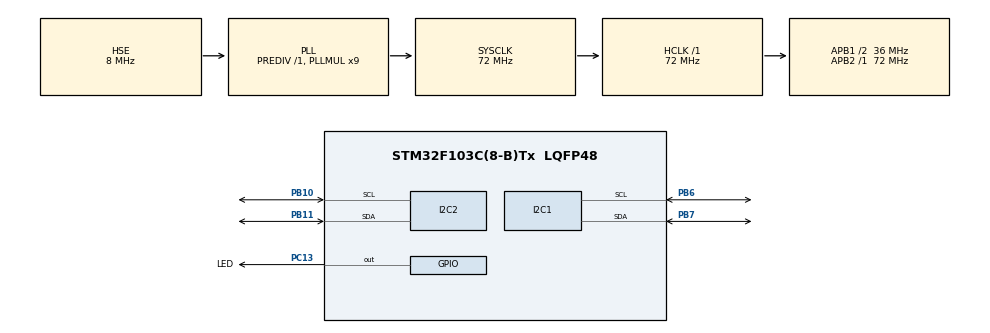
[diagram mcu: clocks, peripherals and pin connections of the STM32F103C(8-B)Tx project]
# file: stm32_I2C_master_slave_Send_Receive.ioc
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Dma.I2C1_RX.0.Direction=DMA_PERIPH_TO_MEMORY
Dma.I2C1_RX.0.Instance=DMA1_Channel7
Dma.I2C1_RX.0.MemDataAlignment=DMA_MDATAALIGN_BYTE
Dma.I2C1_RX.0.MemInc=DMA_MINC_ENABLE
Dma.I2C1_RX.0.Mode=DMA_NORMAL
Dma.I2C1_RX.0.PeriphDataAlignment=DMA_PDATAALIGN_BYTE
Dma.I2C1_RX.0.PeriphInc=DMA_PINC_DISABLE
Dma.I2C1_RX.0.Priority=DMA_PRIORITY_LOW
Dma.I2C1_TX.1.Direction=DMA_MEMORY_TO_PERIPH
Dma.I2C1_TX.1.Instance=DMA1_Channel6
Dma.I2C1_TX.1.MemDataAlignment=DMA_MDATAALIGN_BYTE
Dma.I2C1_TX.1.MemInc=DMA_MINC_ENABLE
Dma.I2C1_TX.1.Mode=DMA_NORMAL
Dma.I2C1_TX.1.PeriphDataAlignment=DMA_PDATAALIGN_BYTE
Dma.I2C1_TX.1.PeriphInc=DMA_PINC_DISABLE
Dma.I2C1_TX.1.Priority=DMA_PRIORITY_LOW
Dma.I2C2_RX.2.Direction=DMA_PERIPH_TO_MEMORY
Dma.I2C2_RX.2.Instance=DMA1_Channel5
Dma.I2C2_RX.2.MemDataAlignment=DMA_MDATAALIGN_BYTE
Dma.I2C2_RX.2.MemInc=DMA_MINC_ENABLE
Dma.I2C2_RX.2.Mode=DMA_NORMAL
Dma.I2C2_RX.2.PeriphDataAlignment=DMA_PDATAALIGN_BYTE
Dma.I2C2_RX.2.PeriphInc=DMA_PINC_DISABLE
Dma.I2C2_RX.2.Priority=DMA_PRIORITY_LOW
Dma.I2C2_TX.3.Direction=DMA_MEMORY_TO_PERIPH
Dma.I2C2_TX.3.Instance=DMA1_Channel4
Dma.I2C2_TX.3.MemDataAlignment=DMA_MDATAALIGN_BYTE
Dma.I2C2_TX.3.MemInc=DMA_MINC_ENABLE
Dma.I2C2_TX.3.Mode=DMA_NORMAL
Dma.I2C2_TX.3.PeriphDataAlignment=DMA_PDATAALIGN_BYTE
Dma.I2C2_TX.3.PeriphInc=DMA_PINC_DISABLE
Dma.I2C2_TX.3.Priority=DMA_PRIORITY_LOW
Dma.Request0=I2C1_RX
Dma.Request1=I2C1_TX
Dma.Request2=I2C2_RX
Dma.Request3=I2C2_TX
I2C1.I2C_Mode=I2C_Fast
I2C1.OwnAddress=I2C1_Address
I2C2.AddressingMode=I2C_ADDRESSINGMODE_7BIT
I2C2.I2C_Mode=I2C_Fast
I2C2.OwnAddress=I2C2_Address
Mcu.Family=STM32F1
Mcu.Name=STM32F103C(8-B)Tx
Mcu.Package=LQFP48
Mcu.UserConstants=I2C1_Address,0x15;I2C2_Address,0x16
NVIC.DMA1_Channel4_IRQn=true\:6\:0\:true\:false\:true\:false\:true
NVIC.DMA1_Channel5_IRQn=true\:6\:0\:true\:false\:true\:false\:true
NVIC.DMA1_Channel6_IRQn=true\:6\:0\:true\:false\:true\:false\:true
NVIC.DMA1_Channel7_IRQn=true\:6\:0\:true\:false\:true\:false\:true
NVIC.I2C1_EV_IRQn=true\:5\:0\:true\:false\:true\:true\:true
NVIC.I2C2_EV_IRQn=true\:5\:0\:true\:false\:true\:true\:true
NVIC.PriorityGroup=NVIC_PRIORITYGROUP_4
NVIC.TIM1_UP_IRQn=true\:0\:0\:false\:false\:true\:true\:true
PA13.Mode=Serial_Wire
PA13.Signal=SYS_JTMS-SWDIO
PA14.Mode=Serial_Wire
PA14.Signal=SYS_JTCK-SWCLK
PB10.Mode=I2C
PB10.Signal=I2C2_SCL
PB11.Mode=I2C
PB11.Signal=I2C2_SDA
PB6.Mode=I2C
PB6.Signal=I2C1_SCL
PB7.Mode=I2C
PB7.Signal=I2C1_SDA
PC13-TAMPER-RTC.GPIO_Label=LED
PC13-TAMPER-RTC.Signal=GPIO_Output
PD0-OSC_IN.Mode=HSE-External-Oscillator
PD0-OSC_IN.Signal=RCC_OSC_IN
PD1-OSC_OUT.Mode=HSE-External-Oscillator
PD1-OSC_OUT.Signal=RCC_OSC_OUT
ProjectManager.HeapSize=0x200
ProjectManager.StackSize=0x400
ProjectManager.TargetToolchain=STM32CubeIDE
RCC.AHBFreq_Value=72000000
RCC.APB1CLKDivider=RCC_HCLK_DIV2
RCC.APB1Freq_Value=36000000
RCC.APB1TimFreq_Value=72000000
RCC.APB2Freq_Value=72000000
RCC.APB2TimFreq_Value=72000000
RCC.EnbaleCSS=true
RCC.HCLKFreq_Value=72000000
RCC.PLLMUL=RCC_PLL_MUL9
RCC.PLLSourceVirtual=RCC_PLLSOURCE_HSE
RCC.SYSCLKFreq_VALUE=72000000
RCC.SYSCLKSource=RCC_SYSCLKSOURCE_PLLCLK
RCC.USBFreq_Value=72000000
TIM1.Period=2000
TIM1.Prescaler=36000
VP_CRC_VS_CRC.Mode=CRC_Activate
VP_TIM1_VS_ClockSourceINT.Mode=Internal
board=custom

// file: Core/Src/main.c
/* USER CODE BEGIN Header */
/**
 ******************************************************************************
 * @file           : main.c
 * @brief          : Main program body
 ******************************************************************************
 * @attention
 *
 * <h2><center>&copy; Copyright (c) 2020 STMicroelectronics.
 * All rights reserved.</center></h2>
 *
 * This software component is licensed by ST under BSD 3-Clause license,
 * the "License"; You may not use this file except in compliance with the
 * License. You may obtain a copy of the License at:
 *                        opensource.org/licenses/BSD-3-Clause
 *
 ******************************************************************************
 */
/* USER CODE END Header */

#include "main.h"
#include "crc.h"
#include "dma.h"
#include "i2c.h"
#include "tim.h"
#include "gpio.h"

/* USER CODE BEGIN PV */
uint8_t I2C1_TX_Buff[200];
uint8_t I2C1_RX_Buff[200];
uint8_t I2C2_TX_Buff[200];
uint8_t I2C2_RX_Buff[200];
/* USER CODE END PV */

void SystemClock_Config(void);

int main(void)
{

  /* MCU Configuration--------------------------------------------------------*/

  /* Reset of all peripherals, Initializes the Flash interface and the Systick. */
  HAL_Init();

  /* Configure the system clock */
  SystemClock_Config();

  /* Initialize all configured peripherals */
  MX_GPIO_Init();
  MX_DMA_Init();
  MX_CRC_Init();
  MX_I2C1_Init();
  MX_I2C2_Init();
  MX_TIM1_Init();
  /* USER CODE BEGIN 2 */
  for (uint8_t i = 0; i < 200; i++)
	I2C1_TX_Buff[i] = i;
  /* USER CODE END 2 */

  /* Infinite loop */
  while (1)
  {

    /* USER CODE BEGIN 3 */
	HAL_GPIO_WritePin(LED_GPIO_Port, LED_Pin, GPIO_PIN_SET);
	HAL_I2C_Master_Transmit(&hi2c1, I2C2_Address, I2C1_TX_Buff, 5, 100);
	HAL_GPIO_WritePin(LED_GPIO_Port, LED_Pin, GPIO_PIN_RESET);
	HAL_I2C_Slave_Receive(&hi2c2, I2C2_RX_Buff, 5, 100);
  }
  /* USER CODE END 3 */
}

void SystemClock_Config(void)
{
  RCC_OscInitTypeDef RCC_OscInitStruct = {0};
  RCC_ClkInitTypeDef RCC_ClkInitStruct = {0};

  /** Initializes the CPU, AHB and APB busses clocks
  */
  RCC_OscInitStruct.OscillatorType = RCC_OSCILLATORTYPE_HSE;
  RCC_OscInitStruct.HSEState = RCC_HSE_ON;
  RCC_OscInitStruct.HSEPredivValue = RCC_HSE_PREDIV_DIV1;
  RCC_OscInitStruct.HSIState = RCC_HSI_ON;
  RCC_OscInitStruct.PLL.PLLState = RCC_PLL_ON;
  RCC_OscInitStruct.PLL.PLLSource = RCC_PLLSOURCE_HSE;
  RCC_OscInitStruct.PLL.PLLMUL = RCC_PLL_MUL9;
  if (HAL_RCC_OscConfig(&RCC_OscInitStruct) != HAL_OK)
  {
    Error_Handler();
  }
  /** Initializes the CPU, AHB and APB busses clocks
  */
  RCC_ClkInitStruct.ClockType = RCC_CLOCKTYPE_HCLK|RCC_CLOCKTYPE_SYSCLK
                              |RCC_CLOCKTYPE_PCLK1|RCC_CLOCKTYPE_PCLK2;
  RCC_ClkInitStruct.SYSCLKSource = RCC_SYSCLKSOURCE_PLLCLK;
  RCC_ClkInitStruct.AHBCLKDivider = RCC_SYSCLK_DIV1;
  RCC_ClkInitStruct.APB1CLKDivider = RCC_HCLK_DIV2;
  RCC_ClkInitStruct.APB2CLKDivider = RCC_HCLK_DIV1;

  if (HAL_RCC_ClockConfig(&RCC_ClkInitStruct, FLASH_LATENCY_2) != HAL_OK)
  {
    Error_Handler();
  }
  /** Enables the Clock Security System
  */
  HAL_RCC_EnableCSS();
}

void Error_Handler(void)
{
}

/************************ (C) COPYRIGHT STMicroelectronics *****END OF FILE****/
